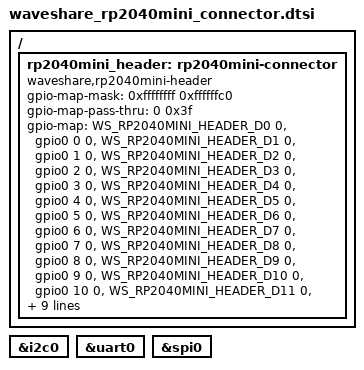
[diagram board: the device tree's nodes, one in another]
/*
 * SPDX-FileCopyrightText: Copyright (c) 2023-2026 TiaC Systems
 * SPDX-License-Identifier: Apache-2.0
 */

#include <zephyr/dt-bindings/gpio/waveshare-rp2040mini-header.h>

/ {
	rp2040mini_header: rp2040mini-connector {
		compatible = "waveshare,rp2040mini-header";
		#gpio-cells = <2>;
		gpio-map-mask = <0xffffffff 0xffffffc0>;
		gpio-map-pass-thru = <0 0x3f>;
		gpio-map = <WS_RP2040MINI_HEADER_D0 0 &gpio0 0 0>,	/* UART0 / GP0 */
			   <WS_RP2040MINI_HEADER_D1 0 &gpio0 1 0>,	/* UART0 / GP1 */
			   <WS_RP2040MINI_HEADER_D2 0 &gpio0 2 0>,	/* GP2 */
			   <WS_RP2040MINI_HEADER_D3 0 &gpio0 3 0>,	/* GP3 */
			   <WS_RP2040MINI_HEADER_D4 0 &gpio0 4 0>,	/* SPI0 / GP4 */
			   <WS_RP2040MINI_HEADER_D5 0 &gpio0 5 0>,	/* SPI0 / GP5 */
			   <WS_RP2040MINI_HEADER_D6 0 &gpio0 6 0>,	/* SPI0 / GP6 */
			   <WS_RP2040MINI_HEADER_D7 0 &gpio0 7 0>,	/* SPI0 / GP7 */
			   <WS_RP2040MINI_HEADER_D8 0 &gpio0 8 0>,	/* I2C0 / GP8 */
			   <WS_RP2040MINI_HEADER_D9 0 &gpio0 9 0>,	/* I2C0 / GP9 */
			   <WS_RP2040MINI_HEADER_D10 0 &gpio0 10 0>,	/* GP10 */
			   <WS_RP2040MINI_HEADER_D11 0 &gpio0 11 0>,	/* GP11 */
			   <WS_RP2040MINI_HEADER_D12 0 &gpio0 12 0>,	/* GP12 */
			   <WS_RP2040MINI_HEADER_D13 0 &gpio0 13 0>,	/* GP13 */
			   <WS_RP2040MINI_HEADER_D14 0 &gpio0 14 0>,	/* I2C1 / GP14 */
			   <WS_RP2040MINI_HEADER_D15 0 &gpio0 15 0>,	/* I2C1 / GP15 */
			   <WS_RP2040MINI_HEADER_A0 0 &gpio0 26 0>,	/* ADC0 / GP26 */
			   <WS_RP2040MINI_HEADER_A1 0 &gpio0 27 0>,	/* ADC1 / GP27 */
			   <WS_RP2040MINI_HEADER_A2 0 &gpio0 28 0>,	/* ADC2 / GP28 */
			   <WS_RP2040MINI_HEADER_A3 0 &gpio0 29 0>;	/* ADC3 / GP28 */
	};
};

rp2040mini_i2c: &i2c0 {};
rp2040mini_serial: &uart0 {};
rp2040mini_spi: &spi0 {};
